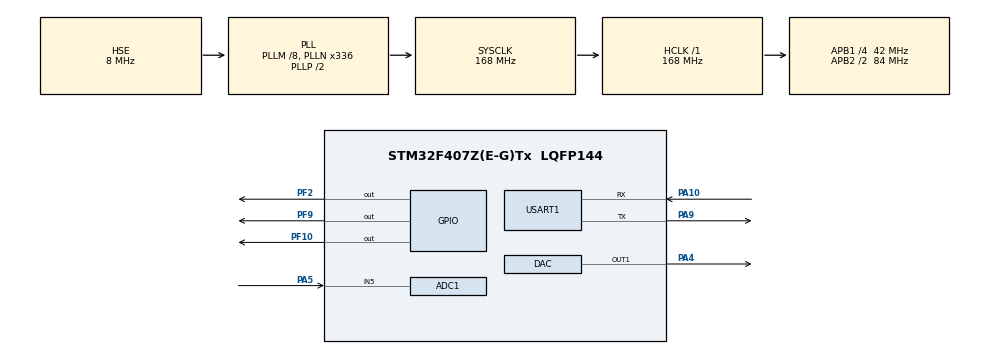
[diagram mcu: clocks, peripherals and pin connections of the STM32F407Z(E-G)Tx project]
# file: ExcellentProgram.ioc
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ADC1.Channel-0\#ChannelRegularConversion=ADC_CHANNEL_5
ADC1.ClockPrescaler=ADC_CLOCK_SYNC_PCLK_DIV6
ADC1.DMAContinuousRequests=ENABLE
ADC1.DiscontinuousConvMode=DISABLE
ADC1.ExternalTrigConv=ADC_EXTERNALTRIGCONV_T8_TRGO
ADC1.NbrOfConversion=1
ADC1.NbrOfConversionFlag=1
ADC1.SamplingTime-0\#ChannelRegularConversion=ADC_SAMPLETIME_56CYCLES
ADC1.ScanConvMode=DISABLE
ADC1.master=1
DAC.DAC_OutputBuffer=DAC_OUTPUTBUFFER_ENABLE
DAC.DAC_Trigger=DAC_TRIGGER_T2_TRGO
Dma.ADC1.0.Direction=DMA_PERIPH_TO_MEMORY
Dma.ADC1.0.FIFOMode=DMA_FIFOMODE_DISABLE
Dma.ADC1.0.Instance=DMA2_Stream0
Dma.ADC1.0.MemDataAlignment=DMA_MDATAALIGN_HALFWORD
Dma.ADC1.0.MemInc=DMA_MINC_ENABLE
Dma.ADC1.0.Mode=DMA_CIRCULAR
Dma.ADC1.0.PeriphDataAlignment=DMA_PDATAALIGN_HALFWORD
Dma.ADC1.0.PeriphInc=DMA_PINC_DISABLE
Dma.ADC1.0.Priority=DMA_PRIORITY_HIGH
Dma.DAC1.1.Direction=DMA_MEMORY_TO_PERIPH
Dma.DAC1.1.FIFOMode=DMA_FIFOMODE_DISABLE
Dma.DAC1.1.Instance=DMA1_Stream5
Dma.DAC1.1.MemDataAlignment=DMA_MDATAALIGN_WORD
Dma.DAC1.1.MemInc=DMA_MINC_ENABLE
Dma.DAC1.1.Mode=DMA_CIRCULAR
Dma.DAC1.1.PeriphDataAlignment=DMA_PDATAALIGN_WORD
Dma.DAC1.1.PeriphInc=DMA_PINC_DISABLE
Dma.DAC1.1.Priority=DMA_PRIORITY_VERY_HIGH
Dma.Request0=ADC1
Dma.Request1=DAC1
Mcu.Family=STM32F4
Mcu.Name=STM32F407Z(E-G)Tx
Mcu.Package=LQFP144
NVIC.DMA1_Stream5_IRQn=true\:1\:0\:true\:false\:true\:false\:true
NVIC.DMA2_Stream0_IRQn=true\:2\:0\:true\:false\:true\:false\:true
NVIC.PriorityGroup=NVIC_PRIORITYGROUP_4
PA10.Mode=Asynchronous
PA10.Signal=USART1_RX
PA4.Signal=COMP_DAC1_group
PA5.Signal=ADCx_IN5
PA9.Mode=Asynchronous
PA9.Signal=USART1_TX
PF10.Signal=GPIO_Output
PF2.GPIO_Speed=GPIO_SPEED_FREQ_VERY_HIGH
PF2.Signal=GPIO_Output
PF9.Signal=GPIO_Output
PH0-OSC_IN.Mode=HSE-External-Oscillator
PH0-OSC_IN.Signal=RCC_OSC_IN
PH1-OSC_OUT.Mode=HSE-External-Oscillator
PH1-OSC_OUT.Signal=RCC_OSC_OUT
ProjectManager.HeapSize=0x200
ProjectManager.StackSize=0x400
ProjectManager.TargetToolchain=SW4STM32
RCC.48MHZClocksFreq_Value=84000000
RCC.AHBFreq_Value=168000000
RCC.APB1CLKDivider=RCC_HCLK_DIV4
RCC.APB1Freq_Value=42000000
RCC.APB1TimFreq_Value=84000000
RCC.APB2CLKDivider=RCC_HCLK_DIV2
RCC.APB2Freq_Value=84000000
RCC.APB2TimFreq_Value=168000000
RCC.CortexFreq_Value=168000000
RCC.HCLKFreq_Value=168000000
RCC.HSE_VALUE=8000000
RCC.HSI_VALUE=16000000
RCC.LSE_VALUE=32768
RCC.PLLM=8
RCC.PLLN=336
RCC.PLLSourceVirtual=RCC_PLLSOURCE_HSE
RCC.SYSCLKFreq_VALUE=168000000
RCC.SYSCLKSource=RCC_SYSCLKSOURCE_PLLCLK
RCC.VCOOutputFreq_Value=336000000
SH.ADCx_IN5.0=ADC1_IN5,IN5
SH.COMP_DAC1_group.0=DAC_OUT1,DAC_OUT1
TIM2.Period=4
TIM2.Prescaler=20
TIM2.TIM_MasterOutputTrigger=TIM_TRGO_UPDATE
TIM8.Period=9
TIM8.Prescaler=20
TIM8.TIM_MasterOutputTrigger=TIM_TRGO_UPDATE
USART1.VirtualMode=VM_ASYNC
VP_TIM2_VS_ClockSourceINT.Mode=Internal
VP_TIM8_VS_ClockSourceINT.Mode=Internal
board=custom

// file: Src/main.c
/* USER CODE BEGIN Header */
/**
  ******************************************************************************
  * @file           : main.c
  * @brief          : Main program body
  ******************************************************************************
  * @attention
  *
  * <h2><center>&copy; Copyright (c) 2020 STMicroelectronics.
  * All rights reserved.</center></h2>
  *
  * This software component is licensed by ST under BSD 3-Clause license,
  * the "License"; You may not use this file except in compliance with the
  * License. You may obtain a copy of the License at:
  *                        opensource.org/licenses/BSD-3-Clause
  *
  ******************************************************************************
  */
/* USER CODE END Header */
#include "main.h"
#include "adc.h"
#include "dac.h"
#include "dma.h"
#include "tim.h"
#include "usart.h"
#include "gpio.h"

/* USER CODE BEGIN Includes */
#include "caculation.h"
/* USER CODE END Includes */

void SystemClock_Config(void);

int main(void)
{

  /* MCU Configuration--------------------------------------------------------*/

  /* Reset of all peripherals, Initializes the Flash interface and the Systick. */
  HAL_Init();

  /* Configure the system clock */
  SystemClock_Config();

  /* Initialize all configured peripherals */
  MX_GPIO_Init();
  MX_DMA_Init();
  MX_ADC1_Init();
  MX_DAC_Init();
  MX_USART1_UART_Init();
  MX_TIM8_Init();
  MX_TIM2_Init();
  /* USER CODE BEGIN 2 */

    Modulation_Init();

    //刚开始初始化

    //HAL_DAC_Start(&hdac,DAC_CHANNEL_1);
    //HAL_ADC_Start_IT(&hadc1);
    //
    printf("Hello!\r\n");
    printf("This is Modulation Project!\r\n");
  /* USER CODE END 2 */

  /* Infinite loop */
  while (1)
  {

    /* USER CODE BEGIN 3 */
      HAL_GPIO_TogglePin(GPIOF,GPIO_PIN_10);
      LED_Inverse();
      printf("Hello!\r\n");
      printf("This is my First GitHub project!\r\n");
      HAL_Delay(500);
  }
  /* USER CODE END 3 */
}

void SystemClock_Config(void)
{
  RCC_OscInitTypeDef RCC_OscInitStruct = {0};
  RCC_ClkInitTypeDef RCC_ClkInitStruct = {0};

  /** Configure the main internal regulator output voltage
  */
  __HAL_RCC_PWR_CLK_ENABLE();
  __HAL_PWR_VOLTAGESCALING_CONFIG(PWR_REGULATOR_VOLTAGE_SCALE1);
  /** Initializes the RCC Oscillators according to the specified parameters
  * in the RCC_OscInitTypeDef structure.
  */
  RCC_OscInitStruct.OscillatorType = RCC_OSCILLATORTYPE_HSE;
  RCC_OscInitStruct.HSEState = RCC_HSE_ON;
  RCC_OscInitStruct.PLL.PLLState = RCC_PLL_ON;
  RCC_OscInitStruct.PLL.PLLSource = RCC_PLLSOURCE_HSE;
  RCC_OscInitStruct.PLL.PLLM = 8;
  RCC_OscInitStruct.PLL.PLLN = 336;
  RCC_OscInitStruct.PLL.PLLP = RCC_PLLP_DIV2;
  RCC_OscInitStruct.PLL.PLLQ = 4;
  if (HAL_RCC_OscConfig(&RCC_OscInitStruct) != HAL_OK)
  {
    Error_Handler();
  }
  /** Initializes the CPU, AHB and APB buses clocks
  */
  RCC_ClkInitStruct.ClockType = RCC_CLOCKTYPE_HCLK|RCC_CLOCKTYPE_SYSCLK
                              |RCC_CLOCKTYPE_PCLK1|RCC_CLOCKTYPE_PCLK2;
  RCC_ClkInitStruct.SYSCLKSource = RCC_SYSCLKSOURCE_PLLCLK;
  RCC_ClkInitStruct.AHBCLKDivider = RCC_SYSCLK_DIV1;
  RCC_ClkInitStruct.APB1CLKDivider = RCC_HCLK_DIV4;
  RCC_ClkInitStruct.APB2CLKDivider = RCC_HCLK_DIV2;

  if (HAL_RCC_ClockConfig(&RCC_ClkInitStruct, FLASH_LATENCY_5) != HAL_OK)
  {
    Error_Handler();
  }
}

void Error_Handler(void)
{
  __disable_irq();
  while (1)
  {
  }
}

/************************ (C) COPYRIGHT STMicroelectronics *****END OF FILE****/
